# WBZ351 register map
Vendor: Microchip
Registers are 32-bit, read-write, reset 0x0 unless marked. A register's access mark holds for its fields unless they carry their own. Addresses are absolute, and some are shared; only a register's first bit layout is shown; [hi:lo] are bit positions.

## DAC_CTRL
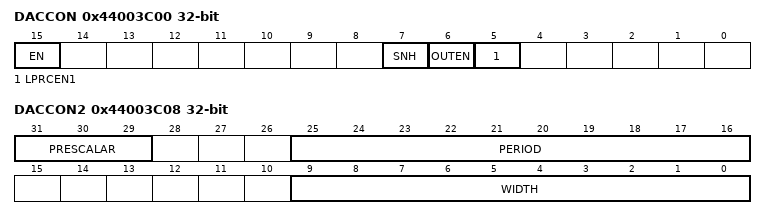
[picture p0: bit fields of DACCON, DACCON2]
0x44003C00 DACCON
  [15] EN — Enable
    0=The peripheral is disabled; 1=The peripheral is enabled
  [7] SNH — Sample and hold circuitry
    0=DAC operation in normal mode; 1=DAC operation in low power mode
  [6] OUTEN — Will enable the output buffer
    0=Output buffer disabled; 1=Output buffer enabled
  [5] LPRCEN1 — LPRC clock enabled for SnH mode
    0=LPRC clock not enabled; 1=LPRC clock enabled
0x44003C04 DACCODE
  [6:0] DATA — DAC data
0x44003C08 DACCON2
  [31:29] PRESCALAR — Prescaling factor for SnH clock
  [25:16] PERIOD — SnH clock period
  [9:0] WIDTH — SnH clock width

## DGI_SPI
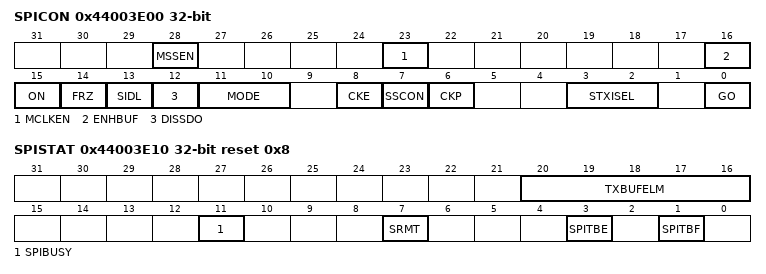
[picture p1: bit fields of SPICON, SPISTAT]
0x44003E00 SPICON
  [28] MSSEN — Master Mode Slave Select Enable bit
    0=Slave select SPI support disabled; 1=SPI Slave Select support enabled
  [23] MCLKEN — Master Clock Enable
    0=PBCLK is used by the BRG; 1=MCLK is used by the BRG
  [16] ENHBUF — Enhanced Buffer Enable bit
    0=Enhanced Buffer Mode is disabled; 1=Enhanced Buffer Mode is enabled
  [15] ON — DGISPI On bit
    0=Turn off and reset macro, disable clocks, disable interrupt event generation, allow SFR modifications; 1=Enable macro
  [14] FRZ — Freeze bit (in Debug Mode)
    0=Continue macro operation when in Debug mode; 1=Break macro operation when in Debug mode
  [13] SIDL — Stop in Idle control bit
    0=Continue to operate in CPU Idle mode; 1=Halt in CPU Idle mode
  [12] DISSDO — Disable SDO bit
    0=SDO pin is controlled by the macro; 1=SDO pin is not used by the macro. Pin controlled by PORT function
  [11:10] MODE — Serial Word Length bits
  [8] CKE — SPI Clock Edge Select bit
    0=Transmit happens on transition from idle clock state to active clock stat e; 1=Transmit happens on transition from active clock state to idle clock state
  [7] SSCON — SSControl bits
    0=SS is not controlled by the DMA module; 1=SS is asserted for the duration of TXCNT
  [6] CKP — Clock Polarity Select bit
    0=Idle state for clock is a low level; active state is a high level; 1=Idle state for clock is a high level; active state is a low level
  [3:2] STXISEL — SPI Transmit Service Request Interrupt SelectFor enhanced buffer mode, the SPI generates a Transmit Service Request when:
    0=The SPIxTXB is empty and SPIxSR is empty (i.e. all transmit operations are complete); 1=The SPIxTXB is empty; 2=The SPIxTXB is at least half empty; 3=The SPIxTXB is not full
  [0] GO — DMA Operation Status bitThis bit is set by the user software to start the DMA operation. It is reset back to zero by the DMA engine whenthe DMA operation is completed or aborted by clearing the ON bit.
    0=DMA is not in operation; 1=DMA is in operation
0x44003E10 SPISTAT ro reset 0x8
  [20:16] TXBUFELM — TransmitBuffer Element Count bits (valid only when ENHBUF = 1)
  [11] SPIBUSY — SPI activity status bit
    0=No on-going transactions (at time of read); 1=Macro currently busy with some transactions
  [7] SRMT — Shift Register (SPIxSR) Empty bit0= There are current or pending transactions
    1=There are no current or pending transactions
  [3] SPITBE — SPI Transmit Buffer Empty status bit
    0=SPIxTXB is not empty; 1=SPIxTXB is empty
  [1] SPITBF — SPI Transmit Buffer Full Status bit
    0=SPIxTXB not full; 1=SPIxTXB is full
0x44003E20 SPIBUF
  [31:0] DATA — FIFO Data bits
0x44003E30 SPIBRG
  [12:0] BRG — Baud Rate Divisor bitsseeSection 2.4.1.
0x44003E40 SPITXADD
  [15:0] TXADD — Transmit Source Address bitsTXADD can constantly be updated to reflect the current transmit address as the transfer progresses
0x44003E50 SPITXCNT
  [15:0] TXCNT — Transmit Count bitsThis register indicates the number of transferred data words. As the DMA progresses, TXCNT is constantly decremented to reflect the remaining count yet to be transferred.
